AUTOSAR XML (schema 4-0-3)
package /AppDsmCtr
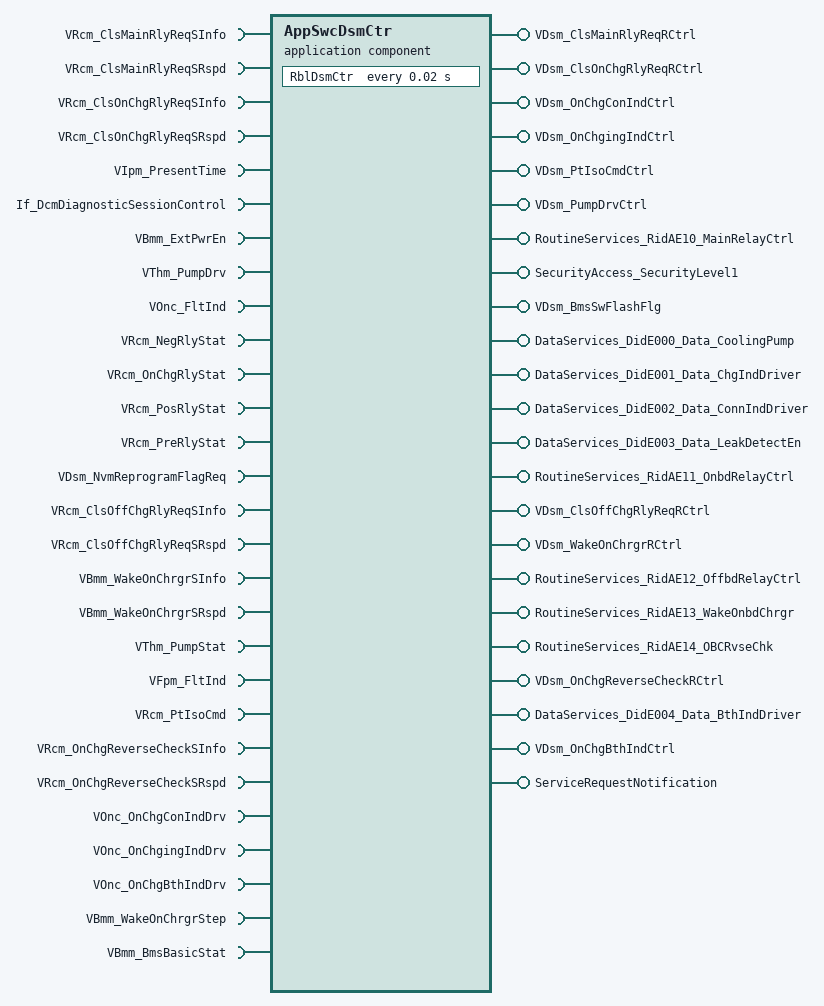
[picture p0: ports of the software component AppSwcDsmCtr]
  application sw component type AppSwcDsmCtr
    4 x require port, all with nonqueued-receiver-com-spec=Enum:
      VRcm_ClsMainRlyReqSInfo: required-interface=VRcm_ClsMainRlyReqSInfo
      VRcm_ClsMainRlyReqSRspd: required-interface=VRcm_ClsMainRlyReqSRspd
      VRcm_ClsOnChgRlyReqSInfo: required-interface=VRcm_ClsOnChgRlyReqSInfo
      VRcm_ClsOnChgRlyReqSRspd: required-interface=VRcm_ClsOnChgRlyReqSRspd
    9 x provide port:
      VDsm_ClsMainRlyReqRCtrl: nonqueued-sender-com-spec=Enum, provided-interface=VDsm_ClsMainRlyReqRCtrl
      VDsm_ClsOnChgRlyReqRCtrl: nonqueued-sender-com-spec=Flg, provided-interface=VDsm_ClsOnChgRlyReqRCtrl
      VDsm_OnChgConIndCtrl: nonqueued-sender-com-spec=Flg, provided-interface=VDsm_OnChgConIndCtrl
      VDsm_OnChgingIndCtrl: nonqueued-sender-com-spec=Flg, provided-interface=VDsm_OnChgingIndCtrl
      VDsm_PtIsoCmdCtrl: nonqueued-sender-com-spec=Enum, provided-interface=VDsm_PtIsoCmdCtrl
      VDsm_PumpDrvCtrl: nonqueued-sender-com-spec=Flg, provided-interface=VDsm_PumpDrvCtrl
      RoutineServices_RidAE10_MainRelayCtrl: provided-interface=RoutineServices_RidAE10_MainRelayCtrl
      SecurityAccess_SecurityLevel1: provided-interface=SecurityAccess_SecurityLevel1
      VDsm_BmsSwFlashFlg: nonqueued-sender-com-spec=Flg, provided-interface=VDsm_BmsSwFlashFlg
    require port VIpm_PresentTime: nonqueued-receiver-com-spec=Array, required-interface=VIpm_PresentTime
    4 x provide port:
      DataServices_DidE000_Data_CoolingPump: provided-interface=DataServices_DidE000_Data_CoolingPump
      DataServices_DidE001_Data_ChgIndDriver: provided-interface=DataServices_DidE001_Data_ChgIndDriver
      DataServices_DidE002_Data_ConnIndDriver: provided-interface=DataServices_DidE002_Data_ConnIndDriver
      DataServices_DidE003_Data_LeakDetectEn: provided-interface=DataServices_DidE003_Data_LeakDetectEn
    require port If_DcmDiagnosticSessionControl: required-interface=If_DcmDiagnosticSessionControl
    provide port RoutineServices_RidAE11_OnbdRelayCtrl: provided-interface=RoutineServices_RidAE11_OnbdRelayCtrl
    8 x require port:
      VBmm_ExtPwrEn: nonqueued-receiver-com-spec=Flg, required-interface=VBmm_ExtPwrEn
      VThm_PumpDrv: nonqueued-receiver-com-spec=Flg, required-interface=VThm_PumpDrv
      VOnc_FltInd: nonqueued-receiver-com-spec=Array, required-interface=VOnc_FltInd
      VRcm_NegRlyStat: nonqueued-receiver-com-spec=Enum, required-interface=VRcm_NegRlyStat
      VRcm_OnChgRlyStat: nonqueued-receiver-com-spec=Enum, required-interface=VRcm_OnChgRlyStat
      VRcm_PosRlyStat: nonqueued-receiver-com-spec=Enum, required-interface=VRcm_PosRlyStat
      VRcm_PreRlyStat: nonqueued-receiver-com-spec=Enum, required-interface=VRcm_PreRlyStat
      VDsm_NvmReprogramFlagReq: required-interface=VDsm_NvmReprogramFlagReq
    provide port VDsm_ClsOffChgRlyReqRCtrl: nonqueued-sender-com-spec=Flg, provided-interface=VDsm_ClsOffChgRlyReqRCtrl
    provide port VDsm_WakeOnChrgrRCtrl: nonqueued-sender-com-spec=Flg, provided-interface=VDsm_WakeOnChrgrRCtrl
    4 x require port, all with nonqueued-receiver-com-spec=Enum:
      VRcm_ClsOffChgRlyReqSInfo: required-interface=VRcm_ClsOffChgRlyReqSInfo
      VRcm_ClsOffChgRlyReqSRspd: required-interface=VRcm_ClsOffChgRlyReqSRspd
      VBmm_WakeOnChrgrSInfo: required-interface=VBmm_WakeOnChrgrSInfo
      VBmm_WakeOnChrgrSRspd: required-interface=VBmm_WakeOnChrgrSRspd
    provide port RoutineServices_RidAE12_OffbdRelayCtrl: provided-interface=RoutineServices_RidAE12_OffbdRelayCtrl
    provide port RoutineServices_RidAE13_WakeOnbdChrgr: provided-interface=RoutineServices_RidAE13_WakeOnbdChrgr
    require port VThm_PumpStat: nonqueued-receiver-com-spec=Enum, required-interface=VThm_PumpStat
    require port VFpm_FltInd: nonqueued-receiver-com-spec=Array, required-interface=VFpm_FltInd
    require port VRcm_PtIsoCmd: nonqueued-receiver-com-spec=Enum, required-interface=VRcm_PtIsoCmd
    provide port RoutineServices_RidAE14_OBCRvseChk: provided-interface=RoutineServices_RidAE14_OBCRvseChk
    require port VRcm_OnChgReverseCheckSInfo: nonqueued-receiver-com-spec=Enum, required-interface=VRcm_OnChgReverseCheckSInfo
    require port VRcm_OnChgReverseCheckSRspd: nonqueued-receiver-com-spec=Enum, required-interface=VRcm_OnChgReverseCheckSRspd
    provide port VDsm_OnChgReverseCheckRCtrl: nonqueued-sender-com-spec=Enum, provided-interface=VDsm_OnChgReverseCheckRCtrl
    provide port DataServices_DidE004_Data_BthIndDriver: provided-interface=DataServices_DidE004_Data_BthIndDriver
    require port VOnc_OnChgConIndDrv: nonqueued-receiver-com-spec=Enum, required-interface=VOnc_OnChgConIndDrv
    require port VOnc_OnChgingIndDrv: nonqueued-receiver-com-spec=Enum, required-interface=VOnc_OnChgingIndDrv
    provide port VDsm_OnChgBthIndCtrl: nonqueued-sender-com-spec=Flg, provided-interface=VDsm_OnChgBthIndCtrl
    require port VOnc_OnChgBthIndDrv: nonqueued-receiver-com-spec=Enum, required-interface=VOnc_OnChgBthIndDrv
    require port VBmm_WakeOnChrgrStep: nonqueued-receiver-com-spec=Enum, required-interface=VBmm_WakeOnChrgrStep
    provide port ServiceRequestNotification: provided-interface=ServiceRequestNotification
    require port VBmm_BmsBasicStat: nonqueued-receiver-com-spec=Enum, required-interface=VBmm_BmsBasicStat
    behavior IbvDsmCtr: data-type-mapping=DcmModeMappingSet
      25 x operation invoked event:
        OpInvokedEv_RoutineServices_RidAE10_MainRelayCtrl_RequestResults: start-on-event=Run_RoutineServices_RidAE10_MainRelayCtrl_GetResult, operation=RoutineServices_RidAE10_MainRelayCtrl.RequestResults
        OpInvokedEv_RoutineServices_RidAE10_MainRelayCtrl_Start: start-on-event=Run_RoutineServices_RidAE10_MainRelayCtrl_Start, operation=RoutineServices_RidAE10_MainRelayCtrl.Start
        OpInvokedEv_RoutineServices_RidAE10_MainRelayCtrl_Stop: start-on-event=Run_RoutineServices_RidAE10_MainRelayCtrl_Stop, operation=RoutineServices_RidAE10_MainRelayCtrl.Stop
        OpInvokedEv_SecurityAccess_SecurityLevel1_CompareKey: start-on-event=Run_SecurityAccess_SecurityLevel1_CompareKey, operation=SecurityAccess_SecurityLevel1.CompareKey
        OpInvokedEv_SecurityAccess_SecurityLevel1_GetSeed: start-on-event=Run_SecurityAccess_SecurityLevel1_GetSeed, operation=SecurityAccess_SecurityLevel1.GetSeed
        OpInvokedEv_RoutineServices_RidAE11_OnbdRelayCtrl_Stop: start-on-event=Run_RoutineServices_RidAE11_OnbdRelayCtrl_Stop, operation=RoutineServices_RidAE11_OnbdRelayCtrl.Stop
        OpInvokedEv_RoutineServices_RidAE11_OnbdRelayCtrl_Start: start-on-event=Run_RoutineServices_RidAE11_OnbdRelayCtrl_Start, operation=RoutineServices_RidAE11_OnbdRelayCtrl.Start
        OpInvokedEv_RoutineServices_RidAE11_OnbdRelayCtrl_RequestResults: start-on-event=Run_RoutineServices_RidAE11_OnbdRelayCtrl_GetResult, operation=RoutineServices_RidAE11_OnbdRelayCtrl.RequestResults
        OpInvokedEv_DataServices_DidE002_Data_ConnIndDriver_ReadData1: start-on-event=Run_IOCtrl_DidE002_Data_ConnIndDriver_ReadDID, operation=DataServices_DidE002_Data_ConnIndDriver.ReadData
        OpInvokedEv_DataServices_DidE003_Data_LeakDetectEn_ReadData: start-on-event=Run_IOCtrl_DidE003_Data_LeakDetectEn_ReadDID, operation=DataServices_DidE003_Data_LeakDetectEn.ReadData
        OpInvokedEv_DataServices_DidE000_Data_CoolingPump_ReadData: start-on-event=Run_IOCtrl_DidE000_Data_CoolingPump_ReadDID, operation=DataServices_DidE000_Data_CoolingPump.ReadData
        OpInvokedEv_DataServices_DidE001_Data_ChgIndDriver_ReadData: start-on-event=Run_IOCtrl_DidE001_Data_ChgIndDriver_ReadDID, operation=DataServices_DidE001_Data_ChgIndDriver.ReadData
        OpInvokedEv_DataServices_DidE000_Data_CoolingPump_FreezeCurrentState: start-on-event=Run_IOCtrl_DidE000_Data_CoolingPump_FreezeCurrentState, operation=DataServices_DidE000_Data_CoolingPump.FreezeCurrentState
        OpInvokedEv_DataServices_DidE000_Data_CoolingPump_ReturnControlToECU: start-on-event=Run_IOCtrl_DidE000_Data_CoolingPump_ReturnControlToECU, operation=DataServices_DidE000_Data_CoolingPump.ReturnControlToECU
        OpInvokedEv_DataServices_DidE000_Data_CoolingPump_ShortTermAdjustment: start-on-event=Run_IOCtrl_DidE000_Data_CoolingPump_ShortTermAdjustment, operation=DataServices_DidE000_Data_CoolingPump.ShortTermAdjustment
        OpInvokedEv_DataServices_DidE001_Data_ChgIndDriver_FreezeCurrentState: start-on-event=Run_IOCtrl_DidE001_Data_ChgIndDriver_FreezeCurrentState, operation=DataServices_DidE001_Data_ChgIndDriver.FreezeCurrentState
        OpInvokedEv_DataServices_DidE001_Data_ChgIndDriver_ReturnControlToECU: start-on-event=Run_IOCtrl_DidE001_Data_ChgIndDriver_ReturnControlToECU, operation=DataServices_DidE001_Data_ChgIndDriver.ReturnControlToECU
        OpInvokedEv_DataServices_DidE001_Data_ChgIndDriver_ShortTermAdjustment: start-on-event=Run_IOCtrl_DidE001_Data_ChgIndDriver_ShortTermAdjustment, operation=DataServices_DidE001_Data_ChgIndDriver.ShortTermAdjustment
        OpInvokedEv_DataServices_DidE002_Data_ConnIndDriver_FreezeCurrentState: start-on-event=Run_IOCtrl_DidE002_Data_ConnIndDriver_FreezeCurrentStat, operation=DataServices_DidE002_Data_ConnIndDriver.FreezeCurrentState
        OpInvokedEv_DataServices_DidE002_Data_ConnIndDriver_ReturnControlToECU: start-on-event=Run_IOCtrl_DidE002_Data_ConnIndDriver_ReturnControlToECU, operation=DataServices_DidE002_Data_ConnIndDriver.ReturnControlToECU
        OpInvokedEv_DataServices_DidE002_Data_ConnIndDriver_ShortTermAdjustment: start-on-event=Run_IOCtrl_DidE002_Data_ConnIndDriver_ShortTermAdjustment, operation=DataServices_DidE002_Data_ConnIndDriver.ShortTermAdjustment
        OpInvokedEv_DataServices_DidE003_Data_LeakDetectEn_FreezeCurrentState: start-on-event=Run_IOCtrl_DidE003_Data_LeakDetectEn_FreezeCurrentStat, operation=DataServices_DidE003_Data_LeakDetectEn.FreezeCurrentState
        OpInvokedEv_DataServices_DidE003_Data_LeakDetectEn_ReturnControlToECU: start-on-event=Run_IOCtrl_DidE003_Data_LeakDetectEn_ReturnControlToECU, operation=DataServices_DidE003_Data_LeakDetectEn.ReturnControlToECU
        OpInvokedEv_DataServices_DidE003_Data_LeakDetectEn_ShortTermAdjustment: start-on-event=Run_IOCtrl_DidE003_Data_LeakDetectEn_ShortTermAdjustment, operation=DataServices_DidE003_Data_LeakDetectEn.ShortTermAdjustment
        OpInvokedEv_DataServices_DidE000_Data_CoolingPump_ConditionCheckRead: start-on-event=Run_IOCtrl_DidE000_Data_CoolingPump_ConditionCheckRead, operation=DataServices_DidE000_Data_CoolingPump.ConditionCheckRead
      timing event TeDsmCtr: start-on-event=RblDsmCtr, period=0.02
      22 x operation invoked event:
        OpInvokedEv_DataServices_DidE000_Data_CoolingPump_ResetToDefault: start-on-event=Run_IOCtrl_DidE000_Data_CoolingPump_ResetToDefault, operation=DataServices_DidE000_Data_CoolingPump.ResetToDefault
        OpInvokedEv_DataServices_DidE001_Data_ChgIndDriver_ConditionCheckRead: start-on-event=Run_IOCtrl_DidE001_Data_ChgIndDriver_ConditionCheckRead, operation=DataServices_DidE001_Data_ChgIndDriver.ConditionCheckRead
        OpInvokedEv_DataServices_DidE001_Data_ChgIndDriver_ResetToDefault: start-on-event=Run_IOCtrl_DidE001_Data_ChgIndDriver_ResetToDefault, operation=DataServices_DidE001_Data_ChgIndDriver.ResetToDefault
        OpInvokedEv_DataServices_DidE002_Data_ConnIndDriver_ConditionCheckRead: start-on-event=Run_IOCtrl_DidE002_Data_ConnIndDriver_ConditionCheckRead, operation=DataServices_DidE002_Data_ConnIndDriver.ConditionCheckRead
        OpInvokedEv_DataServices_DidE002_Data_ConnIndDriver_ResetToDefault: start-on-event=Run_IOCtrl_DidE002_Data_ConnIndDriver_ResetToDefault, operation=DataServices_DidE002_Data_ConnIndDriver.ResetToDefault
        OpInvokedEv_DataServices_DidE003_Data_LeakDetectEn_ConditionCheckRead: start-on-event=Run_IOCtrl_DidE003_Data_LeakDetectEn_ConditionCheckRead, operation=DataServices_DidE003_Data_LeakDetectEn.ConditionCheckRead
        OpInvokedEv_DataServices_DidE003_Data_LeakDetectEn_ResetToDefault: start-on-event=Run_IOCtrl_DidE003_Data_LeakDetectEn_ResetToDefault, operation=DataServices_DidE003_Data_LeakDetectEn.ResetToDefault
        OpInvokedEv_RoutineServices_RidAE12_OffbdRelayCtrl_RequestResults: start-on-event=Run_RoutineServices_RidAE12_OffbdRelayCtrl_GetResult, operation=RoutineServices_RidAE12_OffbdRelayCtrl.RequestResults
        OpInvokedEv_RoutineServices_RidAE12_OffbdRelayCtrl_Start: start-on-event=Run_RoutineServices_RidAE12_OffbdRelayCtrl_Start, operation=RoutineServices_RidAE12_OffbdRelayCtrl.Start
        OpInvokedEv_RoutineServices_RidAE12_OffbdRelayCtrl_Stop: start-on-event=Run_RoutineServices_RidAE12_OffbdRelayCtrl_Stop, operation=RoutineServices_RidAE12_OffbdRelayCtrl.Stop
        OpInvokedEv_RoutineServices_RidAE13_WakeOnbdChrgr_RequestResults: start-on-event=Run_RoutineServices_RidAE13_WakeOnbdChrgr_GetResult, operation=RoutineServices_RidAE13_WakeOnbdChrgr.RequestResults
        OpInvokedEv_RoutineServices_RidAE13_WakeOnbdChrgr_Start: start-on-event=Run_RoutineServices_RidAE13_WakeOnbdChrgr_Start, operation=RoutineServices_RidAE13_WakeOnbdChrgr.Start
        OpInvokedEv_RoutineServices_RidAE14_OBCRvseChk_RequestResults: start-on-event=Run_RoutineServices_RidAE14_OBCRvseChk_GetResult, operation=RoutineServices_RidAE14_OBCRvseChk.RequestResults
        OpInvokedEv_RoutineServices_RidAE14_OBCRvseChk_Start: start-on-event=Run_RoutineServices_RidAE14_OBCRvseChk_Start, operation=RoutineServices_RidAE14_OBCRvseChk.Start
        OpInvokedEv_DataServices_DidE004_Data_BthIndDriver_ConditionCheckRead: start-on-event=Run_IOCtrl_DidE004_Data_BthIndDriver_ConditionCheckRead, operation=DataServices_DidE004_Data_BthIndDriver.ConditionCheckRead
        OpInvokedEv_DataServices_DidE004_Data_BthIndDriver_FreezeCurrentState: start-on-event=Run_IOCtrl_DidE004_Data_BthIndDriver_FreezeCurrentStat, operation=DataServices_DidE004_Data_BthIndDriver.FreezeCurrentState
        OpInvokedEv_DataServices_DidE004_Data_BthIndDriver_ReadData: start-on-event=Run_IOCtrl_DidE004_Data_BthIndDriver_ReadDID, operation=DataServices_DidE004_Data_BthIndDriver.ReadData
        OpInvokedEv_DataServices_DidE004_Data_BthIndDriver_ResetToDefault: start-on-event=Run_IOCtrl_DidE004_Data_BthIndDriver_ResetToDefault, operation=DataServices_DidE004_Data_BthIndDriver.ResetToDefault
        OpInvokedEv_DataServices_DidE004_Data_BthIndDriver_ReturnControlToECU: start-on-event=Run_IOCtrl_DidE004_Data_BthIndDriver_ReturnControlToECU, operation=DataServices_DidE004_Data_BthIndDriver.ReturnControlToECU
        OpInvokedEv_DataServices_DidE004_Data_BthIndDriver_ShortTermAdjustment: start-on-event=Run_IOCtrl_DidE004_Data_BthIndDriver_ShortTermAdjustment, operation=DataServices_DidE004_Data_BthIndDriver.ShortTermAdjustment
        OpInvokedEv_ServiceRequestNotification_Confirmation: start-on-event=Run_ServiceRequestNotification_Confirmation, operation=ServiceRequestNotification.Confirmation
        OpInvokedEv_ServiceRequestNotification_Indication: start-on-event=Run_ServiceRequestNotification_Indication, operation=ServiceRequestNotification.Indication
      explicit-inter-runnable-variables:
        6 x data:
          IrvSeed: type=Dcm_DataBuffer4FixedType
          Irv_VDsm_ClsMainRlyReqRCtrl_Enum: type=Signal_Uint
          Irv_VDsm_ClsOffChgRlyReqRCtrl_Flg: type=Signal_Uint
          Irv_VDsm_ClsOnChgRlyReqRCtrl_Flg: type=Signal_Uint
          Irv_VDsm_OnChgReverseCheckRCtrl_Enum: type=Signal_Uint
          Irv_VDsm_WakeOnChrgrRCtrl_Flg: type=Signal_Uint
      48 x runnable, all with can-be-invoked-concurrently=true:
        RblDsmCtr: mode-access-point=If_DcmDiagnosticSessionControl.DcmDiagnosticSessionControl, symbol=sym_RblDsmCtr
          data-receive-point-by-arguments:
            5 x access:
              ArgRecPoint_VRcm_NegRlyStat_Enum: accessed-variable=VRcm_NegRlyStat.Enum
              ArgRecPoint_VRcm_OnChgRlyStat_Enum: accessed-variable=VRcm_OnChgRlyStat.Enum
              ArgRecPoint_VRcm_PosRlyStat_Enum: accessed-variable=VRcm_PosRlyStat.Enum
              ArgRecPoint_VRcm_PreRlyStat_Enum: accessed-variable=VRcm_PreRlyStat.Enum
              ArgRecPoint_VBmm_WakeOnChrgrSInfo_Enum: accessed-variable=VBmm_WakeOnChrgrSInfo.Enum
          data-send-points:
            6 x access:
              SendPoint_VDsm_BmsSwFlashFlg_Flg: accessed-variable=VDsm_BmsSwFlashFlg.Flg
              SendPoint_VDsm_ClsMainRlyReqRCtrl_Enum: accessed-variable=VDsm_ClsMainRlyReqRCtrl.Enum
              SendPoint_VDsm_ClsOnChgRlyReqRCtrl_Flg: accessed-variable=VDsm_ClsOnChgRlyReqRCtrl.Flg
              SendPoint_VDsm_ClsOffChgRlyReqRCtrl_Flg: accessed-variable=VDsm_ClsOffChgRlyReqRCtrl.Flg
              SendPoint_VDsm_WakeOnChrgrRCtrl_Flg: accessed-variable=VDsm_WakeOnChrgrRCtrl.Flg
              SendPoint_VDsm_OnChgReverseCheckRCtrl_Enum: accessed-variable=VDsm_OnChgReverseCheckRCtrl.Enum
          read-local-variables:
            5 x access:
              VariableAccess1: accessed-variable=Irv_VDsm_ClsMainRlyReqRCtrl_Enum
              VariableAccess2: accessed-variable=Irv_VDsm_ClsOffChgRlyReqRCtrl_Flg
              VariableAccess3: accessed-variable=Irv_VDsm_ClsOnChgRlyReqRCtrl_Flg
              VariableAccess4: accessed-variable=Irv_VDsm_OnChgReverseCheckRCtrl_Enum
              VariableAccess5: accessed-variable=Irv_VDsm_WakeOnChrgrRCtrl_Flg
          sync call SynchSrvCallPoint_VDsm_NvmReprogramFlagReq_NvmReprogramFlagReq: operation=VDsm_NvmReprogramFlagReq.NvmReprogramFlagReq, timeout=0.0
        Run_RoutineServices_RidAE10_MainRelayCtrl_Start: symbol=sym_Run_RoutineServices_RidAE10_MainRelayCtrl_Start
          data-receive-point-by-arguments:
            access ArgRecPoint_VRcm_ClsMainRlyReqSRspd_Enum: accessed-variable=VRcm_ClsMainRlyReqSRspd.Enum
          written-local-variables:
            access VariableAccess1: accessed-variable=Irv_VDsm_ClsMainRlyReqRCtrl_Enum
        Run_RoutineServices_RidAE10_MainRelayCtrl_Stop: symbol=sym_Run_RoutineServices_RidAE10_MainRelayCtrl_Stop
          data-receive-point-by-arguments:
            access ArgRecPoint_VRcm_ClsMainRlyReqSRspd_Enum: accessed-variable=VRcm_ClsMainRlyReqSRspd.Enum
          written-local-variables:
            access VariableAccess1: accessed-variable=Irv_VDsm_ClsMainRlyReqRCtrl_Enum
        Run_RoutineServices_RidAE10_MainRelayCtrl_GetResult: symbol=sym_Run_RoutineServices_RidAE10_MainRelayCtrl_GetResult
          data-receive-point-by-arguments:
            access ArgRecPoint_VRcm_ClsMainRlyReqSInfo_Enum: accessed-variable=VRcm_ClsMainRlyReqSInfo.Enum
        Run_SecurityAccess_SecurityLevel1_CompareKey: symbol=sym_Run_SecurityAccess_SecurityLevel1_CompareKey
          read-local-variables:
            access VariableAccess1: accessed-variable=IrvSeed
        Run_SecurityAccess_SecurityLevel1_GetSeed: symbol=sym_Run_SecurityAccess_SecurityLevel1_GetSeed
          data-receive-point-by-arguments:
            access ArgRecPoint_VIpm_PresentTime_Array: accessed-variable=VIpm_PresentTime.Array
          written-local-variables:
            access VariableAccess1: accessed-variable=IrvSeed
        Run_IOCtrl_DidE000_Data_CoolingPump_ReadDID: symbol=sym_Run_IOCtrl_DidE000_Data_CoolingPump_ReadDID
          data-receive-point-by-arguments:
            access ArgRecPoint_VThm_PumpDrv_Flg: accessed-variable=VThm_PumpDrv.Flg
            access ArgRecPoint_VThm_PumpStat_Enum: accessed-variable=VThm_PumpStat.Enum
        Run_IOCtrl_DidE001_Data_ChgIndDriver_ReadDID: symbol=sym_Run_IOCtrl_DidE001_Data_ChgIndDriver_ReadDID
          data-receive-point-by-arguments:
            access ArgRecPoint_VOnc_OnChgingIndDrv_Enum: accessed-variable=VOnc_OnChgingIndDrv.Enum
        Run_IOCtrl_DidE002_Data_ConnIndDriver_ReadDID: symbol=sym_Run_IOCtrl_DidE002_Data_ConnIndDriver_ReadDID
          data-receive-point-by-arguments:
            access ArgRecPoint_VOnc_OnChgConIndDrv_Enum: accessed-variable=VOnc_OnChgConIndDrv.Enum
        Run_IOCtrl_DidE003_Data_LeakDetectEn_ReadDID: symbol=sym_Run_IOCtrl_DidE003_Data_LeakDetectEn_ReadDID
          data-receive-point-by-arguments:
            access ArgRecPoint_VRcm_PtIsoCmd_Enum: accessed-variable=VRcm_PtIsoCmd.Enum
        Run_RoutineServices_RidAE11_OnbdRelayCtrl_Start: symbol=sym_Run_RoutineServices_RidAE11_OnbdRelayCtrl_Start
          data-receive-point-by-arguments:
            access ArgRecPoint_VRcm_ClsOnChgRlyReqSRspd_Enum: accessed-variable=VRcm_ClsOnChgRlyReqSRspd.Enum
          written-local-variables:
            access VariableAccess1: accessed-variable=Irv_VDsm_ClsOnChgRlyReqRCtrl_Flg
        Run_RoutineServices_RidAE11_OnbdRelayCtrl_Stop: symbol=sym_Run_RoutineServices_RidAE11_OnbdRelayCtrl_Stop
          data-receive-point-by-arguments:
            access ArgRecPoint_VRcm_ClsOnChgRlyReqSRspd_Enum: accessed-variable=VRcm_ClsOnChgRlyReqSRspd.Enum
          written-local-variables:
            access VariableAccess1: accessed-variable=Irv_VDsm_ClsOnChgRlyReqRCtrl_Flg
        Run_RoutineServices_RidAE11_OnbdRelayCtrl_GetResult: symbol=sym_Run_RoutineServices_RidAE11_OnbdRelayCtrl_GetResult
          data-receive-point-by-arguments:
            access ArgRecPoint_VRcm_ClsOnChgRlyReqSInfo_Enum: accessed-variable=VRcm_ClsOnChgRlyReqSInfo.Enum
        Run_IOCtrl_DidE000_Data_CoolingPump_FreezeCurrentState: symbol=sym_Run_IOCtrl_DidE000_Data_CoolingPump_FreezeCurrentState
          data-receive-point-by-arguments:
            access ArgRecPoint_VThm_PumpDrv_Flg: accessed-variable=VThm_PumpDrv.Flg
          data-send-points:
            access SendPoint_VDsm_PumpDrvCtrl_Flg: accessed-variable=VDsm_PumpDrvCtrl.Flg
        Run_IOCtrl_DidE001_Data_ChgIndDriver_FreezeCurrentState: symbol=sym_Run_IOCtrl_DidE001_Data_ChgIndDriver_FreezeCurrentState
          data-receive-point-by-arguments:
            access ArgRecPoint_VOnc_FltInd_Array: accessed-variable=VOnc_FltInd.Array
            access ArgRecPoint_VOnc_OnChgingIndDrv_Enum: accessed-variable=VOnc_OnChgingIndDrv.Enum
          data-send-points:
            access SendPoint_VDsm_OnChgingIndCtrl_Flg: accessed-variable=VDsm_OnChgingIndCtrl.Flg
        Run_IOCtrl_DidE002_Data_ConnIndDriver_FreezeCurrentStat: symbol=sym_Run_IOCtrl_DidE002_Data_ConnIndDriver_FreezeCurrentStat
          data-receive-point-by-arguments:
            access ArgRecPoint_VOnc_FltInd_Array: accessed-variable=VOnc_FltInd.Array
            access ArgRecPoint_VOnc_OnChgConIndDrv_Enum: accessed-variable=VOnc_OnChgConIndDrv.Enum
          data-send-points:
            access SendPoint_VDsm_OnChgConIndCtrl_Flg: accessed-variable=VDsm_OnChgConIndCtrl.Flg
        Run_IOCtrl_DidE003_Data_LeakDetectEn_FreezeCurrentStat: symbol=sym_Run_IOCtrl_DidE003_Data_LeakDetectEn_FreezeCurrentStat
          data-receive-point-by-arguments:
            access ArgRecPoint_VBmm_ExtPwrEn_Flg: accessed-variable=VBmm_ExtPwrEn.Flg
            access ArgRecPoint_VRcm_PtIsoCmd_Enum: accessed-variable=VRcm_PtIsoCmd.Enum
          data-send-points:
            access SendPoint_VDsm_PtIsoCmdCtrl_Enum: accessed-variable=VDsm_PtIsoCmdCtrl.Enum
        Run_IOCtrl_DidE000_Data_CoolingPump_ReturnControlToECU: symbol=sym_Run_IOCtrl_DidE000_Data_CoolingPump_ReturnControlToECU
          data-send-points:
            access SendPoint_VDsm_PumpDrvCtrl_Flg: accessed-variable=VDsm_PumpDrvCtrl.Flg
        Run_IOCtrl_DidE001_Data_ChgIndDriver_ReturnControlToECU: symbol=sym_Run_IOCtrl_DidE001_Data_ChgIndDriver_ReturnControlToECU
          data-receive-point-by-arguments:
            access ArgRecPoint_VOnc_FltInd_Array: accessed-variable=VOnc_FltInd.Array
          data-send-points:
            access SendPoint_VDsm_OnChgingIndCtrl_Flg: accessed-variable=VDsm_OnChgingIndCtrl.Flg
        Run_IOCtrl_DidE003_Data_LeakDetectEn_ReturnControlToECU: symbol=sym_Run_IOCtrl_DidE003_Data_LeakDetectEn_ReturnControlToECU
          data-receive-point-by-arguments:
            access ArgRecPoint_VBmm_ExtPwrEn_Flg: accessed-variable=VBmm_ExtPwrEn.Flg
          data-send-points:
            access SendPoint_VDsm_PtIsoCmdCtrl_Enum: accessed-variable=VDsm_PtIsoCmdCtrl.Enum
        Run_IOCtrl_DidE002_Data_ConnIndDriver_ReturnControlToECU: symbol=sym_Run_IOCtrl_DidE002_Data_ConnIndDriver_ReturnControlToECU
          data-receive-point-by-arguments:
            access ArgRecPoint_VOnc_FltInd_Array: accessed-variable=VOnc_FltInd.Array
          data-send-points:
            access SendPoint_VDsm_OnChgConIndCtrl_Flg: accessed-variable=VDsm_OnChgConIndCtrl.Flg
        Run_IOCtrl_DidE001_Data_ChgIndDriver_ShortTermAdjustment: symbol=sym_Run_IOCtrl_DidE001_Data_ChgIndDriver_ShortTermAdjustment
          data-receive-point-by-arguments:
            access ArgRecPoint_VOnc_FltInd_Array: accessed-variable=VOnc_FltInd.Array
          data-send-points:
            access SendPoint_VDsm_OnChgingIndCtrl_Flg: accessed-variable=VDsm_OnChgingIndCtrl.Flg
        Run_IOCtrl_DidE000_Data_CoolingPump_ShortTermAdjustment: symbol=sym_Run_IOCtrl_DidE000_Data_CoolingPump_ShortTermAdjustment
          data-receive-point-by-arguments:
            access ArgRecPoint_VFpm_FltInd_Array: accessed-variable=VFpm_FltInd.Array
          data-send-points:
            access SendPoint_VDsm_PumpDrvCtrl_Flg: accessed-variable=VDsm_PumpDrvCtrl.Flg
        Run_IOCtrl_DidE002_Data_ConnIndDriver_ShortTermAdjustment: symbol=sym_Run_IOCtrl_DidE002_Data_ConnIndDriver_ShortTermAdjustment
          data-receive-point-by-arguments:
            access ArgRecPoint_VOnc_FltInd_Array: accessed-variable=VOnc_FltInd.Array
          data-send-points:
            access SendPoint_VDsm_OnChgConIndCtrl_Flg: accessed-variable=VDsm_OnChgConIndCtrl.Flg
        Run_IOCtrl_DidE003_Data_LeakDetectEn_ShortTermAdjustment: symbol=sym_Run_IOCtrl_DidE003_Data_LeakDetectEn_ShortTermAdjustment
          data-receive-point-by-arguments:
            access ArgRecPoint_VBmm_ExtPwrEn_Flg: accessed-variable=VBmm_ExtPwrEn.Flg
          data-send-points:
            access SendPoint_VDsm_PtIsoCmdCtrl_Enum: accessed-variable=VDsm_PtIsoCmdCtrl.Enum
        Run_IOCtrl_DidE000_Data_CoolingPump_ConditionCheckRead: symbol=sym_Run_IOCtrl_DidE000_Data_CoolingPump_ConditionCheckRead
        Run_IOCtrl_DidE001_Data_ChgIndDriver_ConditionCheckRead: symbol=sym_Run_IOCtrl_DidE001_Data_ChgIndDriver_ConditionCheckRead
        Run_IOCtrl_DidE002_Data_ConnIndDriver_ConditionCheckRead: symbol=sym_Run_IOCtrl_DidE002_Data_ConnIndDriver_ConditionCheckRead
        Run_IOCtrl_DidE003_Data_LeakDetectEn_ConditionCheckRead: symbol=sym_Run_IOCtrl_DidE003_Data_LeakDetectEn_ConditionCheckRead
        Run_IOCtrl_DidE000_Data_CoolingPump_ResetToDefault: symbol=sym_Run_IOCtrl_DidE000_Data_CoolingPump_ResetToDefault
          data-send-points:
            access SendPoint_VDsm_PumpDrvCtrl_Flg: accessed-variable=VDsm_PumpDrvCtrl.Flg
        Run_IOCtrl_DidE001_Data_ChgIndDriver_ResetToDefault: symbol=sym_Run_IOCtrl_DidE001_Data_ChgIndDriver_ResetToDefault
          data-receive-point-by-arguments:
            access ArgRecPoint_VOnc_FltInd_Array: accessed-variable=VOnc_FltInd.Array
          data-send-points:
            access SendPoint_VDsm_OnChgingIndCtrl_Flg: accessed-variable=VDsm_OnChgingIndCtrl.Flg
        Run_IOCtrl_DidE002_Data_ConnIndDriver_ResetToDefault: symbol=sym_Run_IOCtrl_DidE002_Data_ConnIndDriver_ResetToDefault
          data-receive-point-by-arguments:
            access ArgRecPoint_VOnc_FltInd_Array: accessed-variable=VOnc_FltInd.Array
          data-send-points:
            access SendPoint_VDsm_OnChgConIndCtrl_Flg: accessed-variable=VDsm_OnChgConIndCtrl.Flg
        Run_IOCtrl_DidE003_Data_LeakDetectEn_ResetToDefault: symbol=sym_Run_IOCtrl_DidE003_Data_LeakDetectEn_ResetToDefault
          data-receive-point-by-arguments:
            access ArgRecPoint_VBmm_ExtPwrEn_Flg: accessed-variable=VBmm_ExtPwrEn.Flg
          data-send-points:
            access SendPoint_VDsm_PtIsoCmdCtrl_Enum: accessed-variable=VDsm_PtIsoCmdCtrl.Enum
        Run_RoutineServices_RidAE12_OffbdRelayCtrl_GetResult: symbol=sym_Run_RoutineServices_RidAE12_OffbdRelayCtrl_GetResult
          data-receive-point-by-arguments:
            access ArgRecPoint_VRcm_ClsOffChgRlyReqSInfo_Enum: accessed-variable=VRcm_ClsOffChgRlyReqSInfo.Enum
        Run_RoutineServices_RidAE12_OffbdRelayCtrl_Start: symbol=sym_Run_RoutineServices_RidAE12_OffbdRelayCtrl_Start
          data-receive-point-by-arguments:
            access ArgRecPoint_VRcm_ClsOffChgRlyReqSRspd_Enum: accessed-variable=VRcm_ClsOffChgRlyReqSRspd.Enum
          written-local-variables:
            access VariableAccess1: accessed-variable=Irv_VDsm_ClsOffChgRlyReqRCtrl_Flg
        Run_RoutineServices_RidAE12_OffbdRelayCtrl_Stop: symbol=sym_Run_RoutineServices_RidAE12_OffbdRelayCtrl_Stop
          data-receive-point-by-arguments:
            access ArgRecPoint_VRcm_ClsOffChgRlyReqSRspd_Enum: accessed-variable=VRcm_ClsOffChgRlyReqSRspd.Enum
          written-local-variables:
            access VariableAccess1: accessed-variable=Irv_VDsm_ClsOffChgRlyReqRCtrl_Flg
        Run_RoutineServices_RidAE13_WakeOnbdChrgr_GetResult: symbol=sym_Run_RoutineServices_RidAE13_WakeOnbdChrgr_GetResult
          data-receive-point-by-arguments:
            access ArgRecPoint_VBmm_WakeOnChrgrSInfo_Enum: accessed-variable=VBmm_WakeOnChrgrSInfo.Enum
        Run_RoutineServices_RidAE13_WakeOnbdChrgr_Start: symbol=sym_Run_RoutineServices_RidAE13_WakeOnbdChrgr_Start
          data-receive-point-by-arguments:
            access ArgRecPoint_VBmm_WakeOnChrgrSRspd_Enum: accessed-variable=VBmm_WakeOnChrgrSRspd.Enum
            access ArgRecPoint_VBmm_WakeOnChrgrSInfo_Enum: accessed-variable=VBmm_WakeOnChrgrSInfo.Enum
            access ArgRecPoint_VBmm_WakeOnChrgrStep_Enum: accessed-variable=VBmm_WakeOnChrgrStep.Enum
          written-local-variables:
            access VariableAccess1: accessed-variable=Irv_VDsm_WakeOnChrgrRCtrl_Flg
        Run_RoutineServices_RidAE14_OBCRvseChk_GetResult: symbol=sym_Run_RoutineServices_RidAE14_OBCRvseChk_GetResult
          data-receive-point-by-arguments:
            access ArgRecPoint_VRcm_OnChgReverseCheckSInfo_Enum: accessed-variable=VRcm_OnChgReverseCheckSInfo.Enum
        Run_RoutineServices_RidAE14_OBCRvseChk_Start: symbol=sym_Run_RoutineServices_RidAE14_OBCRvseChk_Start
          data-receive-point-by-arguments:
            access ArgRecPoint_VRcm_OnChgReverseCheckSRspd_Enum: accessed-variable=VRcm_OnChgReverseCheckSRspd.Enum
            access ArgRecPoint_VRcm_OnChgReverseCheckSInfo_Enum: accessed-variable=VRcm_OnChgReverseCheckSInfo.Enum
          written-local-variables:
            access VariableAccess1: accessed-variable=Irv_VDsm_OnChgReverseCheckRCtrl_Enum
        Run_IOCtrl_DidE004_Data_BthIndDriver_ConditionCheckRead: symbol=sym_Run_IOCtrl_DidE004_Data_BthIndDriver_ConditionCheckRead
        Run_IOCtrl_DidE004_Data_BthIndDriver_ReadDID: symbol=sym_Run_IOCtrl_DidE004_Data_BthIndDriver_ReadDID
          data-receive-point-by-arguments:
            access ArgRecPoint_VOnc_OnChgBthIndDrv_Enum: accessed-variable=VOnc_OnChgBthIndDrv.Enum
        Run_IOCtrl_DidE004_Data_BthIndDriver_ResetToDefault: symbol=sym_Run_IOCtrl_DidE004_Data_BthIndDriver_ResetToDefault
          data-receive-point-by-arguments:
            access ArgRecPoint_VOnc_FltInd_Array: accessed-variable=VOnc_FltInd.Array
          data-send-points:
            access SendPoint_VDsm_OnChgBthIndCtrl_Flg: accessed-variable=VDsm_OnChgBthIndCtrl.Flg
        Run_IOCtrl_DidE004_Data_BthIndDriver_ReturnControlToECU: symbol=sym_Run_IOCtrl_DidE004_Data_BthIndDriver_ReturnControlToECU
          data-receive-point-by-arguments:
            access ArgRecPoint_VOnc_FltInd_Array: accessed-variable=VOnc_FltInd.Array
          data-send-points:
            access SendPoint_VDsm_OnChgBthIndCtrl_Flg: accessed-variable=VDsm_OnChgBthIndCtrl.Flg
        Run_IOCtrl_DidE004_Data_BthIndDriver_ShortTermAdjustment: symbol=sym_Run_IOCtrl_DidE004_Data_BthIndDriver_ShortTermAdjustment
          data-receive-point-by-arguments:
            access ArgRecPoint_VOnc_FltInd_Array: accessed-variable=VOnc_FltInd.Array
          data-send-points:
            access SendPoint_VDsm_OnChgBthIndCtrl_Flg: accessed-variable=VDsm_OnChgBthIndCtrl.Flg
        Run_IOCtrl_DidE004_Data_BthIndDriver_FreezeCurrentStat: symbol=sym_Run_IOCtrl_DidE004_Data_BthIndDriver_FreezeCurrentStat
          data-receive-point-by-arguments:
            access ArgRecPoint_VOnc_FltInd_Array: accessed-variable=VOnc_FltInd.Array
            access ArgRecPoint_VOnc_OnChgBthIndDrv_Enum: accessed-variable=VOnc_OnChgBthIndDrv.Enum
          data-send-points:
            access SendPoint_VDsm_OnChgBthIndCtrl_Flg: accessed-variable=VDsm_OnChgBthIndCtrl.Flg
        Run_ServiceRequestNotification_Confirmation: mode-access-point=If_DcmDiagnosticSessionControl.DcmDiagnosticSessionControl, symbol=sym_Run_ServiceRequestNotification_Confirmation
          data-receive-point-by-arguments:
            access ArgRecPoint_VBmm_BmsBasicStat_Enum: accessed-variable=VBmm_BmsBasicStat.Enum
        Run_ServiceRequestNotification_Indication: mode-access-point=If_DcmDiagnosticSessionControl.DcmDiagnosticSessionControl, symbol=sym_Run_ServiceRequestNotification_Indication
          data-receive-point-by-arguments:
            access ArgRecPoint_VBmm_BmsBasicStat_Enum: accessed-variable=VBmm_BmsBasicStat.Enum
  swc implementation ImpDsmCtr: programming-language=C, sw-version=1.0.0, vendor-id=31, behavior=IbvDsmCtr
